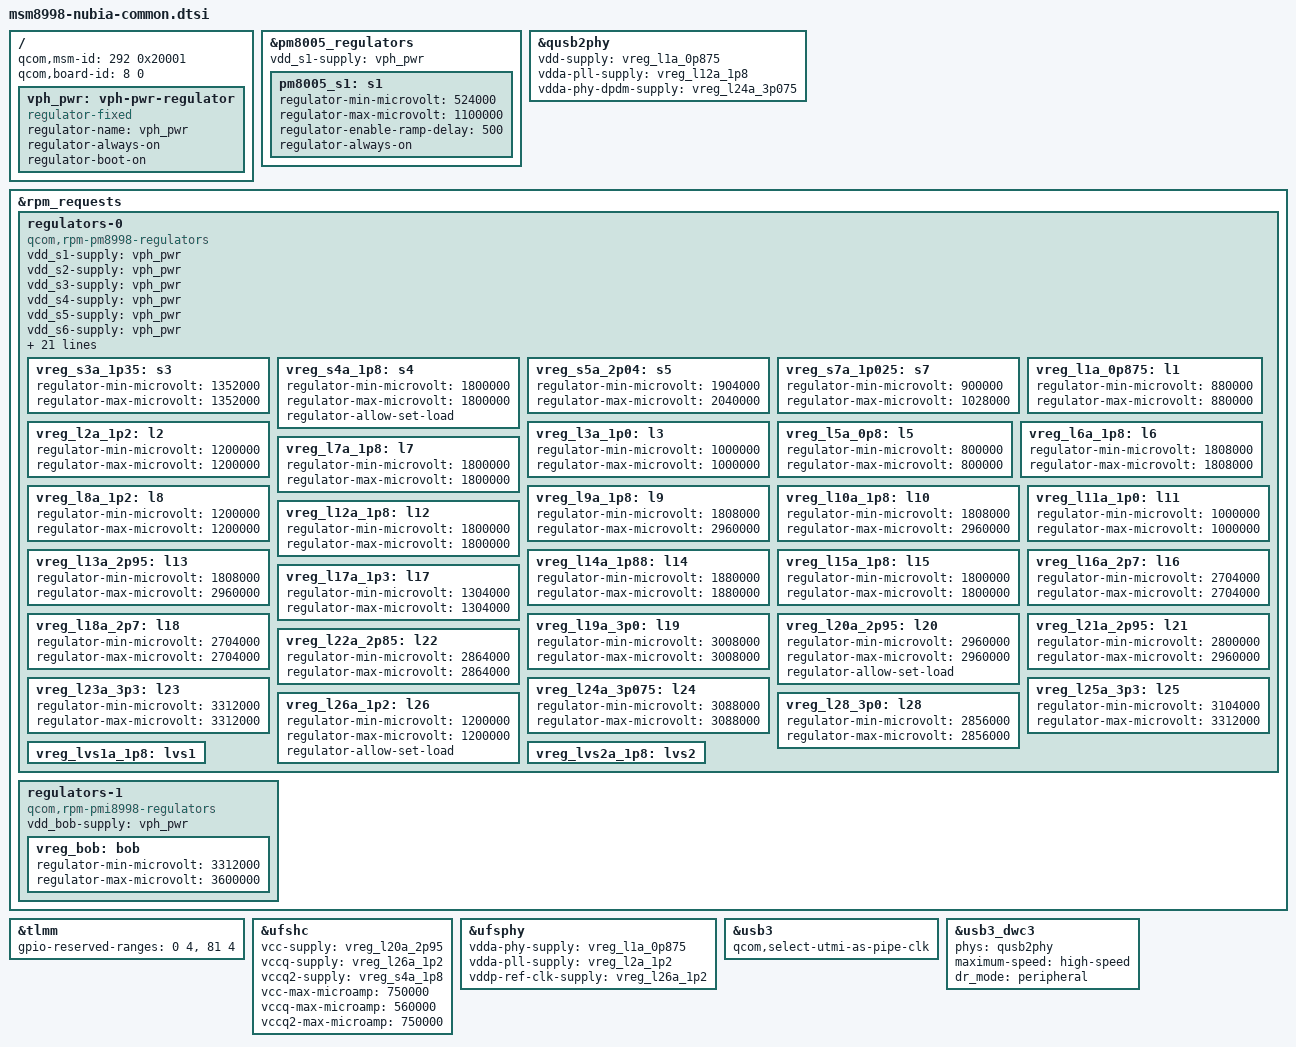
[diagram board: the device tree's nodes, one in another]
// SPDX-License-Identifier: BSD-3-Clause
/*
 * Copyright (c) 2025, Giovanni Ricca <giovanniricca@proton.me>
 */

/dts-v1/;

#include "msm8998.dtsi"
#include "pm8005.dtsi"
#include "pm8998.dtsi"
#include "pmi8998.dtsi"

/ {
	/* required for bootloader to select correct board */
	qcom,msm-id = <292 0x20001>; /* 8998 v2.1 */
	qcom,board-id = <8 0>;

	vph_pwr: vph-pwr-regulator {
		compatible = "regulator-fixed";
		regulator-name = "vph_pwr";
		regulator-always-on;
		regulator-boot-on;
	};
};

&pm8005_regulators {
	vdd_s1-supply = <&vph_pwr>;

	pm8005_s1: s1 { /* VDD_GFX supply */
		regulator-min-microvolt = <524000>;
		regulator-max-microvolt = <1100000>;
		regulator-enable-ramp-delay = <500>;

		/* Hack until we rig up the gpu consumer */
		regulator-always-on;
	};
};

&qusb2phy {
	status = "okay";

	vdd-supply = <&vreg_l1a_0p875>;
	vdda-pll-supply = <&vreg_l12a_1p8>;
	vdda-phy-dpdm-supply = <&vreg_l24a_3p075>;
};

&rpm_requests {
	regulators-0 {
		compatible = "qcom,rpm-pm8998-regulators";

		vdd_s1-supply = <&vph_pwr>;
		vdd_s2-supply = <&vph_pwr>;
		vdd_s3-supply = <&vph_pwr>;
		vdd_s4-supply = <&vph_pwr>;
		vdd_s5-supply = <&vph_pwr>;
		vdd_s6-supply = <&vph_pwr>;
		vdd_s7-supply = <&vph_pwr>;
		vdd_s8-supply = <&vph_pwr>;
		vdd_s9-supply = <&vph_pwr>;
		vdd_s10-supply = <&vph_pwr>;
		vdd_s11-supply = <&vph_pwr>;
		vdd_s12-supply = <&vph_pwr>;
		vdd_s13-supply = <&vph_pwr>;
		vdd_l1_l27-supply = <&vreg_s7a_1p025>;
		vdd_l2_l8_l17-supply = <&vreg_s3a_1p35>;
		vdd_l3_l11-supply = <&vreg_s7a_1p025>;
		vdd_l4_l5-supply = <&vreg_s7a_1p025>;
		vdd_l6-supply = <&vreg_s5a_2p04>;
		vdd_l7_l12_l14_l15-supply = <&vreg_s5a_2p04>;
		vdd_l9-supply = <&vreg_bob>;
		vdd_l10_l23_l25-supply = <&vreg_bob>;
		vdd_l13_l19_l21-supply = <&vreg_bob>;
		vdd_l16_l28-supply = <&vreg_bob>;
		vdd_l18_l22-supply = <&vreg_bob>;
		vdd_l20_l24-supply = <&vreg_bob>;
		vdd_l26-supply = <&vreg_s3a_1p35>;
		vdd_lvs1_lvs2-supply = <&vreg_s4a_1p8>;

		vreg_s3a_1p35: s3 {
			regulator-min-microvolt = <1352000>;
			regulator-max-microvolt = <1352000>;
		};

		vreg_s4a_1p8: s4 {
			regulator-min-microvolt = <1800000>;
			regulator-max-microvolt = <1800000>;
			regulator-allow-set-load;
		};

		vreg_s5a_2p04: s5 {
			regulator-min-microvolt = <1904000>;
			regulator-max-microvolt = <2040000>;
		};

		vreg_s7a_1p025: s7 {
			regulator-min-microvolt = <900000>;
			regulator-max-microvolt = <1028000>;
		};

		vreg_l1a_0p875: l1 {
			regulator-min-microvolt = <880000>;
			regulator-max-microvolt = <880000>;
		};

		vreg_l2a_1p2: l2 {
			regulator-min-microvolt = <1200000>;
			regulator-max-microvolt = <1200000>;
		};

		vreg_l3a_1p0: l3 {
			regulator-min-microvolt = <1000000>;
			regulator-max-microvolt = <1000000>;
		};

		vreg_l5a_0p8: l5 {
			regulator-min-microvolt = <800000>;
			regulator-max-microvolt = <800000>;
		};

		vreg_l6a_1p8: l6 {
			regulator-min-microvolt = <1808000>;
			regulator-max-microvolt = <1808000>;
		};

		vreg_l7a_1p8: l7 {
			regulator-min-microvolt = <1800000>;
			regulator-max-microvolt = <1800000>;
		};

		vreg_l8a_1p2: l8 {
			regulator-min-microvolt = <1200000>;
			regulator-max-microvolt = <1200000>;
		};

		vreg_l9a_1p8: l9 {
			regulator-min-microvolt = <1808000>;
			regulator-max-microvolt = <2960000>;
		};

		vreg_l10a_1p8: l10 {
			regulator-min-microvolt = <1808000>;
			regulator-max-microvolt = <2960000>;
		};

		vreg_l11a_1p0: l11 {
			regulator-min-microvolt = <1000000>;
			regulator-max-microvolt = <1000000>;
		};

		vreg_l12a_1p8: l12 {
			regulator-min-microvolt = <1800000>;
			regulator-max-microvolt = <1800000>;
		};

		vreg_l13a_2p95: l13 {
			regulator-min-microvolt = <1808000>;
			regulator-max-microvolt = <2960000>;
		};

		vreg_l14a_1p88: l14 {
			regulator-min-microvolt = <1880000>;
			regulator-max-microvolt = <1880000>;
		};

		vreg_l15a_1p8: l15 {
			regulator-min-microvolt = <1800000>;
			regulator-max-microvolt = <1800000>;
		};

		vreg_l16a_2p7: l16 {
			regulator-min-microvolt = <2704000>;
			regulator-max-microvolt = <2704000>;
		};

		vreg_l17a_1p3: l17 {
			regulator-min-microvolt = <1304000>;
			regulator-max-microvolt = <1304000>;
		};

		vreg_l18a_2p7: l18 {
			regulator-min-microvolt = <2704000>;
			regulator-max-microvolt = <2704000>;
		};

		vreg_l19a_3p0: l19 {
			regulator-min-microvolt = <3008000>;
			regulator-max-microvolt = <3008000>;
		};

		vreg_l20a_2p95: l20 {
			regulator-min-microvolt = <2960000>;
			regulator-max-microvolt = <2960000>;
			regulator-allow-set-load;
		};

		vreg_l21a_2p95: l21 {
			regulator-min-microvolt = <2800000>;
			regulator-max-microvolt = <2960000>;
		};

		vreg_l22a_2p85: l22 {
			regulator-min-microvolt = <2864000>;
			regulator-max-microvolt = <2864000>;
		};

		vreg_l23a_3p3: l23 {
			regulator-min-microvolt = <3312000>;
			regulator-max-microvolt = <3312000>;
		};

		vreg_l24a_3p075: l24 {
			/*
			 * HACK: Set min-microvolt to 3V unlike the 1,8V on downstream;
			 *       until we have working plug detection to switch between these
			 *       voltages this shall do so we at least have working USB.
			 */
			regulator-min-microvolt = <3088000>;
			regulator-max-microvolt = <3088000>;
		};

		vreg_l25a_3p3: l25 {
			regulator-min-microvolt = <3104000>;
			regulator-max-microvolt = <3312000>;
		};

		vreg_l26a_1p2: l26 {
			regulator-min-microvolt = <1200000>;
			regulator-max-microvolt = <1200000>;
			regulator-allow-set-load;
		};

		vreg_l28_3p0: l28 {
			regulator-min-microvolt = <2856000>;
			regulator-max-microvolt = <2856000>;
		};

		vreg_lvs1a_1p8: lvs1 { };
		vreg_lvs2a_1p8: lvs2 { };
	};

	regulators-1 {
		compatible = "qcom,rpm-pmi8998-regulators";

		vdd_bob-supply = <&vph_pwr>;

		vreg_bob: bob {
			regulator-min-microvolt = <3312000>;
			regulator-max-microvolt = <3600000>;
		};
	};
};

&tlmm {
	gpio-reserved-ranges = <0 4>, <81 4>;
};

&ufshc {
	status = "okay";
	vcc-supply = <&vreg_l20a_2p95>;
	vccq-supply = <&vreg_l26a_1p2>;
	vccq2-supply = <&vreg_s4a_1p8>;
	vcc-max-microamp = <750000>;
	vccq-max-microamp = <560000>;
	vccq2-max-microamp = <750000>;
};

&ufsphy {
	status = "okay";
	vdda-phy-supply = <&vreg_l1a_0p875>;
	vdda-pll-supply = <&vreg_l2a_1p2>;
	vddp-ref-clk-supply = <&vreg_l26a_1p2>;
};

&usb3 {
	status = "okay";

	/* Disable USB3 pipe_clk requirement */
	qcom,select-utmi-as-pipe-clk;
};

&usb3_dwc3 {
	/* Drop the unused USB 3 PHY */
	phys = <&qusb2phy>;
	phy-names = "usb2-phy";

	/* Fastest mode for USB 2 */
	maximum-speed = "high-speed";

	/* Force to peripheral until we can switch modes */
	dr_mode = "peripheral";
};
